# psoc6_01 register map
Vendor: Cypress Semiconductor; Series: PSoC6_01; File version: 1.0
CPU: CM4 r0p1, little endian, MPU, FPU, VTOR, 3 interrupt priority bits
Registers are 32-bit, read-write, reset 0x0 unless marked. A register's access mark holds for its fields unless they carry their own. Offsets are from the block's base; [hi:lo] are bit positions; {n}, {i} and the like mark numbered series; 'fields as' and 'values as' point back to an identical list; <NAME> marks a mode.

## CPUSS — CPU subsystem (CPUSS)
Base 0x40210000
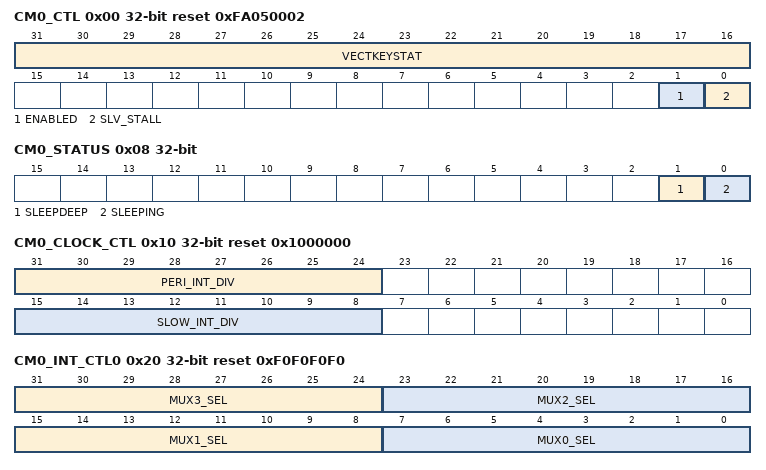
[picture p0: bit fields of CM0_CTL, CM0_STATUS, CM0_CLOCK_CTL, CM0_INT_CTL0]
0x00 CM0_CTL reset 0xFA050002 — CM0+ control
  [31:16] VECTKEYSTAT ro — Register key (to prevent accidental writes). - Should be written with a 0x05fa key value for the write to take effect. - Always reads as 0xfa05.
  [1] ENABLED — Processor enable: '0': Disabled. Processor clock is turned off and reset is activated. After SW clears this field to '0', HW automatically sets this field to '1'. This effectively results in a CM0+ reset, followed by a CM0+ warm boot. '1': Enabled. Note: The intent is that this bit is modified only through an external probe or by the CM4 while the CM0+ is in Sleep or DeepSleep power mode. If this field is cleared to '0' by the CM0+ itself, it should be done under controlled conditions (such that undesirable side effects can be prevented). Note: The CM0+ CPU has a AIRCR.SYSRESETREQ register field that allows the CM0+ to reset the complete device (ENABLED only disables/enables the CM0+), resulting in a warm boot. This CPU register field has similar 'built-in protection' as this CM0_CTL register to prevent accidental system writes (the upper 16-bits of the register need to be written with a 0x05fa key value; see CPU user manual for more details).
  [0] SLV_STALL — Processor debug access control: '0': Access. '1': Stall access. This field is used to stall/delay debug accesses. This is useful to protect execution of code that needs to be protected from debug accesses.
0x08 CM0_STATUS ro
  [1] SLEEPDEEP — Specifies if the CPU is in Sleep or DeepSleep power mode. See SLEEPING field.
  [0] SLEEPING — Specifies if the CPU is in Active, Sleep or DeepSleep power mode: - Active power mode: SLEEPING is '0'. - Sleep power mode: SLEEPING is '1' and SLEEPDEEP is '0'. - DeepSleep power mode: SLEEPING is '1' and SLEEPDEEP is '1'.
0x10 CM0_CLOCK_CTL reset 0x1000000 — CM0+ clock control
  [31:24] PERI_INT_DIV — Specifies the peripheral clock divider (from the high frequency clock 'clk_hf' to the peripheral clock 'clk_peri'). Integer division by (1+PERI_INT_DIV). Allows for integer divisions in the range [1, 256] (PERI_INT_DIV is in the range [0, 255]). Note that this field is retained. However, the counter that is used to implement the division is not and will be initialized by HW to '0' when transitioning from DeepSleep to Active power mode. Note that Fperi <= Fperi_max. Fperi_max is likely to be smaller than Fhf_max. In other words, if Fhf = Fhf_max, PERI_INT_DIV should not be set to '0'.
  [15:8] SLOW_INT_DIV — Specifies the slow clock divider (from the peripheral clock 'clk_peri' to the slow clock 'clk_slow'). Integer division by (1+SLOW_INT_DIV). Allows for integer divisions in the range [1, 256] (SLOW_INT_DIV is in the range [0, 255]). Note that this field is retained. However, the counter that is used to implement the division is not and will be initialized by HW to '0' when transitioning from DeepSleep to Active power mode.
0x20 CM0_INT_CTL0 reset 0xF0F0F0F0 — CM0+ interrupt control 0
  [31:24] MUX3_SEL — System interrupt select for CPU interrupt source 3.
  [23:16] MUX2_SEL — System interrupt select for CPU interrupt source 2.
  [15:8] MUX1_SEL — System interrupt select for CPU interrupt source 1.
  [7:0] MUX0_SEL — System interrupt select for CPU interrupt source 0. If the field value is 240, no system interrupt is connected and the CPU interrupt source is always '0'/de-activated.
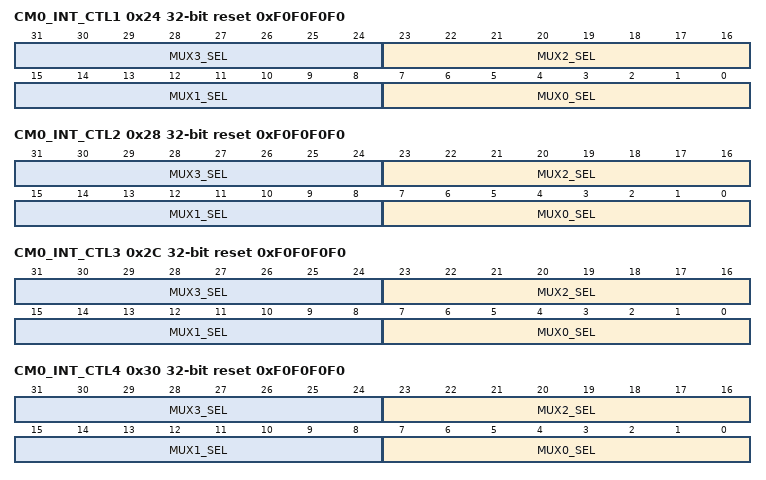
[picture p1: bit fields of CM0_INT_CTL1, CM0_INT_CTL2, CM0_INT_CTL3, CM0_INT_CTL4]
0x24 CM0_INT_CTL1 reset 0xF0F0F0F0 — CM0+ interrupt control 1
  [8n+7:8n] MUX{n}_SEL (n=0..3) — System interrupt select for CPU interrupt source {n+4}.
0x28 CM0_INT_CTL2 reset 0xF0F0F0F0 — CM0+ interrupt control 2
  [8n+7:8n] MUX{n}_SEL (n=0..3) — System interrupt select for CPU interrupt source {n+8}.
0x2C CM0_INT_CTL3 reset 0xF0F0F0F0 — CM0+ interrupt control 3
  [8n+7:8n] MUX{n}_SEL (n=0..3) — System interrupt select for CPU interrupt source {n+12}.
0x30 CM0_INT_CTL4 reset 0xF0F0F0F0 — CM0+ interrupt control 4
  [8n+7:8n] MUX{n}_SEL (n=0..3) — System interrupt select for CPU interrupt source {n+16}.
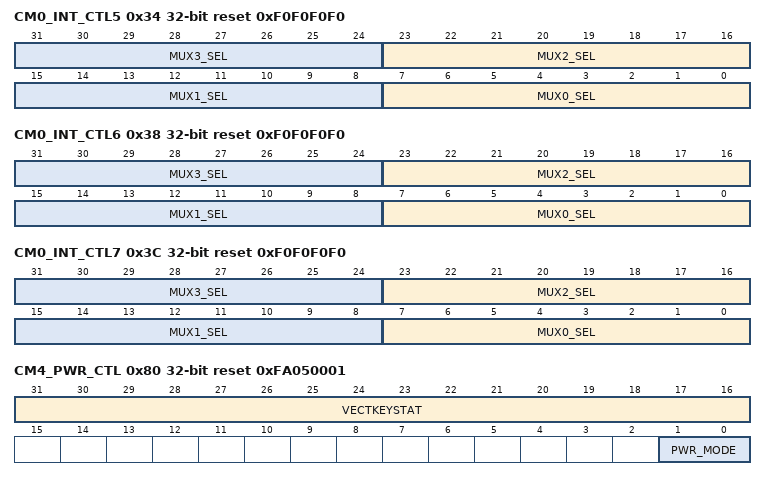
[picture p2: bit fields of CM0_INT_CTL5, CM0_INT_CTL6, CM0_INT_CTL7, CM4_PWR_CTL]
0x34 CM0_INT_CTL5 reset 0xF0F0F0F0 — CM0+ interrupt control 5
  [8n+7:8n] MUX{n}_SEL (n=0..3) — System interrupt select for CPU interrupt source {n+20}.
0x38 CM0_INT_CTL6 reset 0xF0F0F0F0 — CM0+ interrupt control 6
  [8n+7:8n] MUX{n}_SEL (n=0..3) — System interrupt select for CPU interrupt source {n+24}.
0x3C CM0_INT_CTL7 reset 0xF0F0F0F0 — CM0+ interrupt control 7
  [8n+7:8n] MUX{n}_SEL (n=0..3) — System interrupt select for CPU interrupt source {n+28}.
0x80 CM4_PWR_CTL reset 0xFA050001 — CM4 power control
  [31:16] VECTKEYSTAT ro — Register key (to prevent accidental writes). - Should be written with a 0x05fa key value for the write to take effect. - Always reads as 0xfa05.
  [1:0] PWR_MODE — Set Power mode for CM4
    0=OFF (Switch CM4 off Power off, clock off, isolate, reset and no retain.); 1=RESET (Reset CM4 Clock off, no isolated, no retain and reset. Note: The CM4 CPU has a AIRCR.SYSRESETREQ register field that allows the CM4 to reset the complete device (RESET only resets the CM4), resulting in a warm boot.); 2=RETAINED (Put CM4 in Retained mode This can only become effective if CM4 is in SleepDeep mode. Check PWR_DONE flag to see if CM4 RETAINED state has been reached. Power off, clock off, isolate, no reset and retain.); 3=ENABLED (Switch CM4 on. Power on, clock on, no isolate, no reset and no retain.)
0x84 CM4_PWR_DELAY_CTL reset 0x12C — CM4 power control
  [9:0] UP — Number clock cycles delay needed after power domain power up
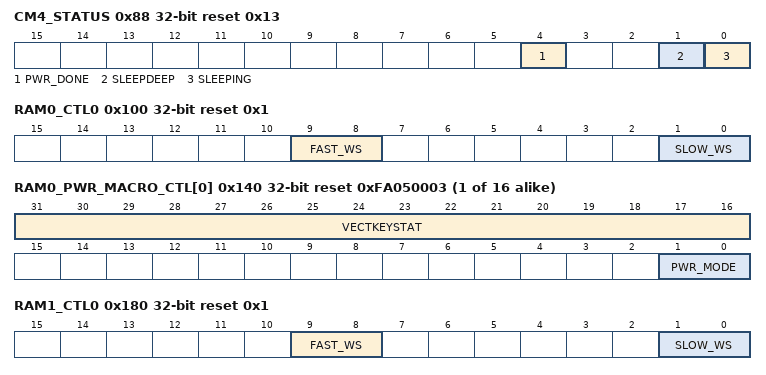
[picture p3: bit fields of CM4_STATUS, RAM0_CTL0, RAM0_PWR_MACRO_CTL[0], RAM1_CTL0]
0x88 CM4_STATUS ro reset 0x13
  [4] PWR_DONE — After a PWR_MODE change this flag indicates if the new power mode has taken effect or not. Note: this flag can also change as a result of a change in debug power up req
  [1] SLEEPDEEP — Specifies if the CPU is in Sleep or DeepSleep power mode. See SLEEPING field.
  [0] SLEEPING — Specifies if the CPU is in Active, Sleep or DeepSleep power mode: - Active power mode: SLEEPING is '0'. - Sleep power mode: SLEEPING is '1' and SLEEPDEEP is '0'. - DeepSleep power mode: SLEEPING is '1' and SLEEPDEEP is '1'.
0x90 CM4_CLOCK_CTL — CM4 clock control
  [15:8] FAST_INT_DIV — Specifies the fast clock divider (from the high frequency clock 'clk_hf' to the peripheral clock 'clk_fast'). Integer division by (1+FAST_INT_DIV). Allows for integer divisions in the range [1, 256] (FAST_INT_DIV is in the range [0, 255]). Note that this field is retained. However, the counter that is used to implement the division is not and will be initialized by HW to '0' when transitioning from DeepSleep to Active power mode.
0xA0 CM4_NMI_CTL reset 0xF0 — CM4 NMI control
  [7:0] MUX0_SEL — System interrupt select for CPU NMI. The reset value ensure that the CPU NMI is NOT connected to any system interrupt after DeepSleep reset.
0x100 RAM0_CTL0 reset 0x1 — RAM 0 control 0
  [9:8] FAST_WS — Memory wait states for the fast clock domain ('clk_fast'). The number of wait states is expressed in 'clk_hf' clock domain cycles.
  [1:0] SLOW_WS — Memory wait states for the slow clock domain ('clk_slow'). The number of wait states is expressed in 'clk_hf' clock domain cycles.
{0x140+4i} RAM0_PWR_MACRO_CTL[{i}] (i=0..15) reset 0xFA050003 — RAM 0 power control
  [31:16] VECTKEYSTAT ro — Register key (to prevent accidental writes). - Should be written with a 0x05fa key value for the write to take effect. - Always reads as 0xfa05.
  [1:0] PWR_MODE — Set Power mode for 1 SRAM0 Macro
    0=OFF (See CM4_PWR_CTL); 1=RSVD (undefined); 2=RETAINED (See CM4_PWR_CTL); 3=ENABLED (See CM4_PWR_CTL)
0x180 RAM1_CTL0 reset 0x1 — RAM 1 control 0
  fields as RAM0_CTL0
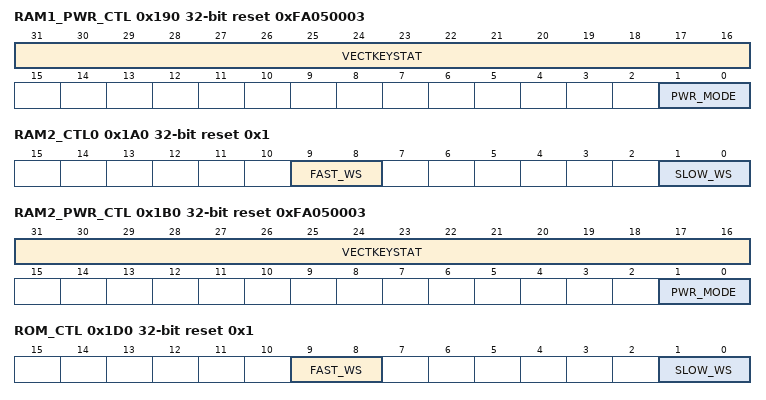
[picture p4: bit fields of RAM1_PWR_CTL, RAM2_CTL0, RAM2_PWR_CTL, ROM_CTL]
0x190 RAM1_PWR_CTL reset 0xFA050003 — RAM1 power control
  [31:16] VECTKEYSTAT ro — Register key (to prevent accidental writes). - Should be written with a 0x05fa key value for the write to take effect. - Always reads as 0xfa05.
  [1:0] PWR_MODE — Set Power mode for SRAM1
    values as RAM0_PWR_MACRO_CTL[0].PWR_MODE
0x1A0 RAM2_CTL0 reset 0x1 — RAM 2 control 0
  fields as RAM0_CTL0
0x1B0 RAM2_PWR_CTL reset 0xFA050003 — RAM2 power control
  [31:16] VECTKEYSTAT ro — Register key (to prevent accidental writes). - Should be written with a 0x05fa key value for the write to take effect. - Always reads as 0xfa05.
  [1:0] PWR_MODE — Set Power mode for SRAM2
    values as RAM0_PWR_MACRO_CTL[0].PWR_MODE
0x1C0 RAM_PWR_DELAY_CTL reset 0x96 — Power up delay used for all SRAM power domains
  fields as CM4_PWR_DELAY_CTL
0x1D0 ROM_CTL reset 0x1 — ROM control
  [9:8] FAST_WS — Memory wait states for the fast clock domain ('clk_fast'). The number of wait states is expressed in 'clk_hf' clock domain cycles.
  [1:0] SLOW_WS — Memory wait states for the slow clock domain ('clk_slow'). The number of wait states is expressed in 'clk_hf' clock domain cycles. Timing paths to and from the memory have a (fixed) minimum duration that always needs to be considered/met. The 'clk_hf' clock domain frequency determines this field's value such that the timing paths minimum duration is met. A table/formula will be provided for this field's values for different 'clk_hf' frequencies.
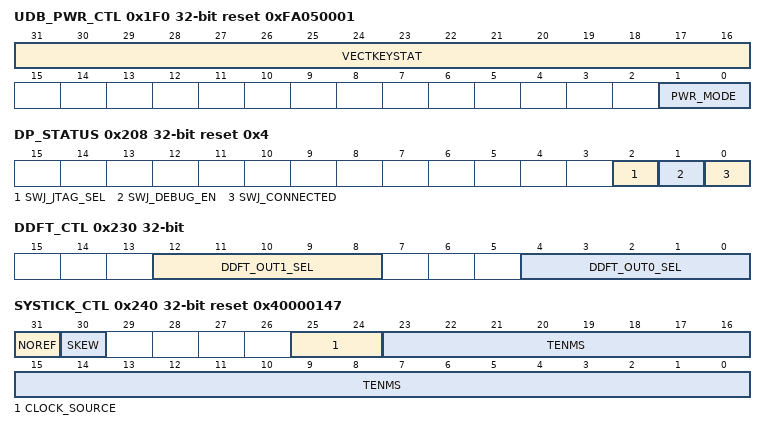
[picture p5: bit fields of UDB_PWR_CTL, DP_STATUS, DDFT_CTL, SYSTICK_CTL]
0x1F0 UDB_PWR_CTL reset 0xFA050001 — UDB power control
  [31:16] VECTKEYSTAT ro — Register key (to prevent accidental writes). - Should be written with a 0x05fa key value for the write to take effect. - Always reads as 0xfa05.
  [1:0] PWR_MODE — Set Power mode for UDBs
    0=OFF (See CM4_PWR_CTL); 1=RESET (See CM4_PWR_CTL); 2=RETAINED (See CM4_PWR_CTL); 3=ENABLED (See CM4_PWR_CTL)
0x1F4 UDB_PWR_DELAY_CTL reset 0x12C — UDB power control
  fields as CM4_PWR_DELAY_CTL
0x208 DP_STATUS ro reset 0x4 — Debug port status
  [2] SWJ_JTAG_SEL — Specifies if the JTAG or SWD interface is selected. This signal is valid when DP_CTL.PTM_SEL is '0' (SWJ mode selected) and SWJ_CONNECTED is '1' (SWJ is connected). '0': SWD selected. '1': JTAG selected.
  [1] SWJ_DEBUG_EN — Specifies if SWJ debug is enabled, i.e. CDBGPWRUPACK is '1' and thus debug clocks are on: '0': Disabled. '1': Enabled.
  [0] SWJ_CONNECTED — Specifies if the SWJ debug port is connected; i.e. debug host interface is active: '0': Not connected/not active. '1': Connected/active.
0x220 BUFF_CTL reset 0x1 — Buffer control
  [0] WRITE_BUFF — Specifies if write transfer can be buffered in the bus infrastructure bridges: '0': Write transfers are not buffered, independent of the transfer's bufferable attribute. '1': Write transfers can be buffered, if the transfer's bufferable attribute indicates that the transfer is a bufferable/posted write.
0x230 DDFT_CTL — DDFT control
  [12:8] DDFT_OUT1_SEL — Select signal for CPUSS DDFT[0] 0: clk_r of the Main flash (which is clk_hf for SONOS Flash) 1: Flash data output bit '0' (r_q[0]) 2: Flash data output bit '32' (r_q[32]) 3: Flash data output bit '64' (r_q[64]) 4: Flash data output bit '127' (r_q[127]) 5: bist_fm_enabled 6: bist_fail 7: cm0_sleeping 8: cm0_sleepdeep 9: cm0_sleep_hold_ack_n 10: cm4_sleeping 11: cm4_sleepdeep 12: cm4_sleep_hold_ack_n 13: cm4_power 14: cm4_act_retain_n 15: cm4_act_isolate_n 16: cm4_enabled 17: cm4_reset_n 18: cm4_pwr_done 19: mmio_ram0_ctl1_power[0] (Power control for SRAM0 macro0) 20: mmio_ram0_ctl1_retain_n[0] (Retention control for SRAM0 macro0) 21: mmio_ram0_ctl1_isolate_n[0] (Isolation control for SRAM0 macro0)
  [4:0] DDFT_OUT0_SEL — Select signal for CPUSS DDFT[0] 0: clk_r of the Main flash (which is clk_hf for SONOS Flash) 1: Flash data output bit '0' (r_q[0]) 2: Flash data output bit '32' (r_q[32]) 3: Flash data output bit '64' (r_q[64]) 4: Flash data output bit '127' (r_q[127]) 5: bist_fm_enabled 6: bist_fail 7: cm0_sleeping 8: cm0_sleepdeep 9: cm0_sleep_hold_ack_n 10: cm4_sleeping 11: cm4_sleepdeep 12: cm4_sleep_hold_ack_n 13: cm4_power 14: cm4_act_retain_n 15: cm4_act_isolate_n 16: cm4_enabled 17: cm4_reset_n 18: cm4_pwr_done 19: mmio_ram0_ctl1_power[0] (Power control for SRAM0 macro0) 20: mmio_ram0_ctl1_retain_n[0] (Retention control for SRAM0 macro0) 21: mmio_ram0_ctl1_isolate_n[0] (Isolation control for SRAM0 macro0)
0x240 SYSTICK_CTL reset 0x40000147 — SysTick timer control
  [31] NOREF — Specifies if an external clock source is provided: '0': An external clock source is provided. '1': An external clock source is NOT provided and only the CPU internal clock can be used as SysTick timer clock source.
  [30] SKEW — Specifies the precision of the clock source and if the TENMS field represents exactly 10 ms (clock source frequency is a multiple of 100 Hz). This affects the suitability of the SysTick timer as a SW real-time clock: '0': Precise. '1': Imprecise.
  [25:24] CLOCK_SOURCE — Specifies an external clock source: '0': The low frequency clock 'clk_lf' is selected. The precision of this clock depends on whether the low frequency clock source is a SRSS internal RC oscillator (imprecise) or a device external crystal oscillator (precise). '1': The internal main oscillator (IMO) clock 'clk_imo' is selected. The MXS40 platform uses a fixed frequency IMO clock. o '2': The external crystal oscillator (ECO) clock 'clk_eco' is selected. '3': The SRSS 'clk_timer' is selected ('clk_timer' is a divided/gated version of 'clk_hf' or 'clk_imo'). Note: If NOREF is '1', the CLOCK_SOURCE value is NOT used. Note: It is SW's responsibility to provide the correct NOREF, SKEW and TENMS field values for the selected clock source.
  [23:0] TENMS — Specifies the number of clock source cycles (minus 1) that make up 10 ms. E.g., for a 32,768 Hz reference clock, TENMS is 328 - 1 = 327.
0x2B0 CM0_VECTOR_TABLE_BASE
  [31:8] ADDR24 — Address of CM0+ vector table. Note: the CM0+ vector table is at an address that is a 256 B multiple.
0x2C0 CM4_VECTOR_TABLE_BASE
  [31:10] ADDR22 — Address of CM4 vector table. Note: the CM4 vector table is at an address that is a 1024 B multiple.
0x320 CM0_PC0_HANDLER — CM0+ protection context 0 handler
  [31:0] ADDR — Address of the protection context 0 handler. This field is used to detect entry to Cypress 'trusted' code through an exception/interrupt.
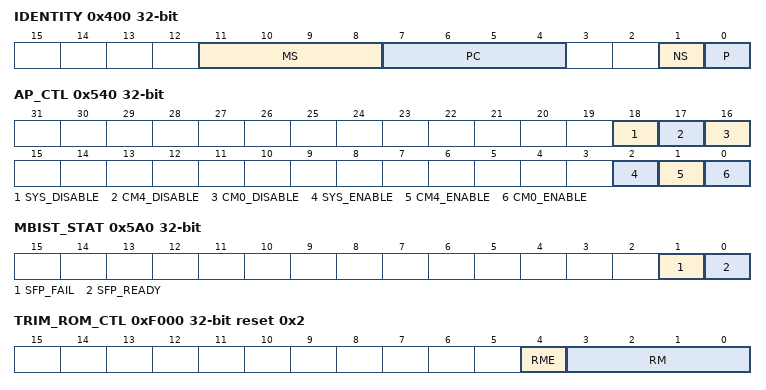
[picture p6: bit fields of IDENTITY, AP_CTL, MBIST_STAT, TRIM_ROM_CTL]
0x400 IDENTITY ro reset not defined
  [11:8] MS — This field specifies the bus master identifier of the transfer that reads the register.
  [7:4] PC — This field specifies the protection context of the transfer that reads the register.
  [1] NS — This field specifies the security setting ('0': secure mode; '1': non-secure mode) of the transfer that reads the register.
  [0] P — This field specifies the privileged setting ('0': user mode; '1': privileged mode) of the transfer that reads the register.
0x500 PROTECTION — Protection status
  [2:0] STATE — Protection state: '0': UNKNOWN. '1': VIRGIN. '2': NORMAL. '3': SECURE. '4': DEAD. The following state transitions are allowed (and enforced by HW): - UNKNOWN => VIRGIN/NORMAL/SECURE/DEAD - NORMAL => DEAD - SECURE => DEAD An attempt to make a NOT allowed state transition will NOT affect this register field.
0x520 CM0_NMI_CTL reset 0xF0 — CM0+ NMI control
  [7:0] MUX0_SEL — System interrupt select for CPU NMI. The reset value ensures that the CPU NMI is NOT connected to any system interrupt after DeepSleep reset.
0x540 AP_CTL — Access port control
  [18] SYS_DISABLE — Disables the system AP interface: '0': Enabled. '1': Disabled. Typically, this field is set by the Cypress boot code with information from eFUSE. The access port is only enabled when SYS_DISABLE is '0' and SYS_ENABLE is '1'.
  [17] CM4_DISABLE — Disables the CM4 AP interface: '0': Enabled. '1': Disabled. Typically, this field is set by the Cypress boot code with information from eFUSE. The access port is only enabled when CM4_DISABLE is '0' and CM4_ENABLE is '1'.
  [16] CM0_DISABLE — Disables the CM0 AP interface: '0': Enabled. '1': Disabled. Typically, this field is set by the Cypress boot code with information from eFUSE. The access port is only enabled when CM0_DISABLE is '0' and CM0_ENABLE is '1'.
  [2] SYS_ENABLE — Enables the system AP interface: '0': Disabled. '1': Enabled.
  [1] CM4_ENABLE — Enables the CM4 AP interface: '0': Disabled. '1': Enabled.
  [0] CM0_ENABLE — Enables the CM0 AP interface: '0': Disabled. '1': Enabled.
0x5A0 MBIST_STAT ro — Memory BIST status
  [1] SFP_FAIL — Report status of the BIST run, only valid if SFP_READY=1
  [0] SFP_READY — Flag indicating the BIST run is done. Note that after starting a BIST run this flag must be set before a new run can be started. For the first BIST run this will be 0.
0xF000 TRIM_ROM_CTL reset 0x2 — ROM trim control
  [4] RME — Read-Write margin enable control. This selects between the default Read-Write margin setting, and the external pin Read-Write margin setting.
  [3:0] RM
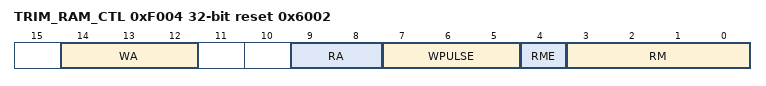
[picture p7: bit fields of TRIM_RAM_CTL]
0xF004 TRIM_RAM_CTL reset 0x6002 — RAM trim control
  [14:12] WA — Write assist enable control (Active High). - WA[1:0] Write Assist pins to control negative voltage on SRAM bitline.
  [9:8] RA — Read Assist control for WL under-drive.
  [7:5] WPULSE — Write Assist Pulse to control pulse width of negative voltage on SRAM bitline.
  [4] RME — Read-Write margin enable control. This selects between the default Read-Write margin setting, and the external RM[3:0] Read-Write margin setting.
  [3:0] RM

## Notices in the file
Copyright 2016-2020 Cypress Semiconductor Corporation
SPDX-License-Identifier: Apache-2.0
Licensed under the Apache License, Version 2.0 (the "License");
you may not use this file except in compliance with the License.
You may obtain a copy of the License at
http://www.apache.org/licenses/LICENSE-2.0
Unless required by applicable law or agreed to in writing, software
distributed under the License is distributed on an "AS IS" BASIS,
WITHOUT WARRANTIES OR CONDITIONS OF ANY KIND, either express or implied.
See the License for the specific language governing permissions and
limitations under the License.
